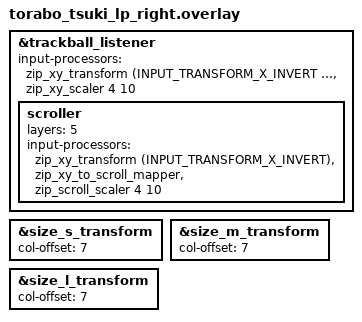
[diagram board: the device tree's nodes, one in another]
#include "torabo_tsuki_lp.dtsi"
#include <input/processors.dtsi>
#include <dt-bindings/zmk/input_transform.h>

&trackball_listener {
    input-processors = <
        &zip_xy_transform (INPUT_TRANSFORM_X_INVERT | INPUT_TRANSFORM_Y_INVERT)
        &zip_xy_scaler 4 10 /* 0.4倍 */
    >;

    scroller {
        layers = <5>;
        input-processors = <
            &zip_xy_transform (INPUT_TRANSFORM_X_INVERT)
            &zip_xy_to_scroll_mapper
            &zip_scroll_scaler 4 10 /* 0.4倍 */
        >;
    };
};

&size_s_transform {
    col-offset = <7>;
};

&size_m_transform {
    col-offset = <7>;
};

&size_l_transform {
    col-offset = <7>;
};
